# AT32F402 register map
Vendor: Keil; Series: AT32F402; File version: 1.0
CPU: CM4 r0p1, little endian, no MPU, FPU, 4 interrupt priority bits
Registers are 32-bit, read-write, reset 0x0 unless marked. A register's access mark holds for its fields unless they carry their own. Offsets are from the block's base; [hi:lo] are bit positions; 'fields as' and 'values as' point back to an identical list.

## ACC — HICK Auto Clock Calibration
Base 0x40017400
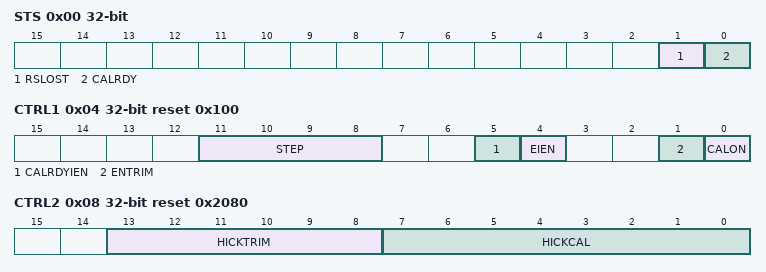
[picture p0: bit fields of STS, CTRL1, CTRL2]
0x00 STS ro — status register
  [1] RSLOST rw — Reference Signal Lost
    0=NotLost (Reference Signal is not lost); 1=Lost (Reference Signal is lost)
  [0] CALRDY rw — Internal high-speed clock calibration ready
    0=NotReady (Interal 8MHz oscillator calibration is not ready); 1=Ready (Interal 8MHz oscillator calibration is ready)
0x04 CTRL1 reset 0x100 — control register 1
  [11:8] STEP — Calibrated step
  [5] CALRDYIEN — CALRDY interrupt enable
    on read: 0=Disabled (Interrupt generation disabled); 1=Enabled (ACC interrupt is generated when CALRDY=1 in the ACC_STS register) | on write: 0=Disable (Interrupt generation disabled); 1=Enable (ACC interrupt is generated when CALRDY=1 in the ACC_STS register)
  [4] EIEN — RSLOST error interrupt enable
    on read: 0=Disabled (Interrupt generation disabled); 1=Enabled (ACC interrupt is generated when RSLOST=1 in the ACC_STS register) | on write: 0=Disable (Interrupt generation disabled); 1=Enable (ACC interrupt is generated when RSLOST=1 in the ACC_STS register)
  [1] ENTRIM — Enable trim
    0=HICKCAL (HICKCAL is calibrated); 1=HICKTRIM (HICKTRIM is calibrated)
  [0] CALON — Calibration on
    on read: 0=Disabled (Calibration disabled); 1=Enabled (Calibration enabled, and starts searching for a pulse on the USB_SOF) | on write: 0=Disable (Calibration disabled); 1=Enable (Calibration enabled, and starts searching for a pulse on the USB_SOF)
0x08 CTRL2 reset 0x2080 — control register 2
  [13:8] HICKTRIM ro — Internal high-speed auto clock trimming
  [7:0] HICKCAL ro — Internal high-speed auto clock calibration
0x0C C1 reset 0x1F2C — compare value 1
  [15:0] C1 — Compare 1
0x10 C2 reset 0x1F40 — compare value 2
  [15:0] C2 — Compare 2
0x14 C3 reset 0x1F54 — compare value 3
  [15:0] C3 — Compare 3

## I2SF5 — Serial peripheral interface
Base 0x40015000
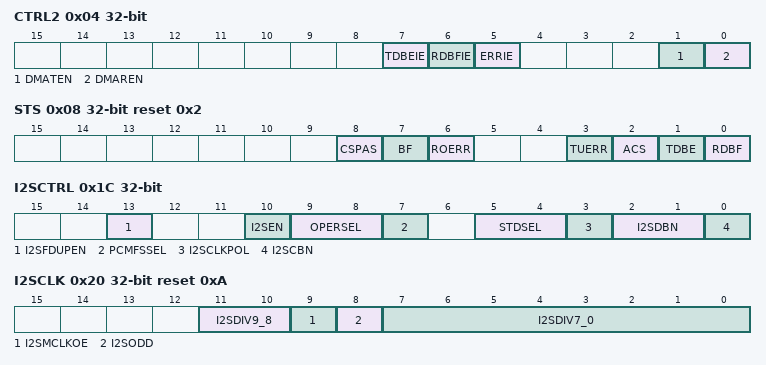
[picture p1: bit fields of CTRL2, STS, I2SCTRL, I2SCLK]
0x04 CTRL2 — control register 2
  [7] TDBEIE — Transmit data buffer empty interrupt enable
  [6] RDBFIE — Receive data buffer full interrupt enable
  [5] ERRIE — Error interrupt enable
  [1] DMATEN — DMA transmit enable
  [0] DMAREN — DMA receive enable
0x08 STS reset 0x2 — status register
  [8] CSPAS — CS pulse abnormal setting fiag
  [7] BF ro — Busy flag
  [6] ROERR ro — Receiver overflow error
  [3] TUERR ro — Transmitter underload error
  [2] ACS ro — Audio channel state
  [1] TDBE ro — Transmit data buffer empty
  [0] RDBF ro — Receive data buffer full
0x0C DT — data register
  [15:0] DT — Data value
0x1C I2SCTRL — I2S control register
  [13] I2SFDUPEN — I2S full duplex mode enable
  [10] I2SEN — I2S Enable
  [9:8] OPERSEL — I2S operation select
  [7] PCMFSSEL — PCM frame synchronization select
  [5:4] STDSEL — I2S standard select
  [3] I2SCLKPOL — I2S clock polarity
  [2:1] I2SDBN — I2S data bit num
  [0] I2SCBN — I2S channel bit num
0x20 I2SCLK reset 0xA — I2S clock register
  [11:10] I2SDIV9_8 — I2S division bit9 and bit8
  [9] I2SMCLKOE — I2S master clock output enable
  [8] I2SODD — Odd result for I2S division
  [7:0] I2SDIV7_0 — I2S division bit7 to bit0
0x30 MISC1
  [0] I2SFPCMCKSEL — I2S PCM clock edge select

## ADCCOM — ADC common area
Base 0x40012300
0x04 CCTRL — Common control register
  [19:16] ADCDIV — ADC division

## DEBUG — Debug support
Base 0xE0042000
0x00 IDCODE ro — DEBUG IDCODE
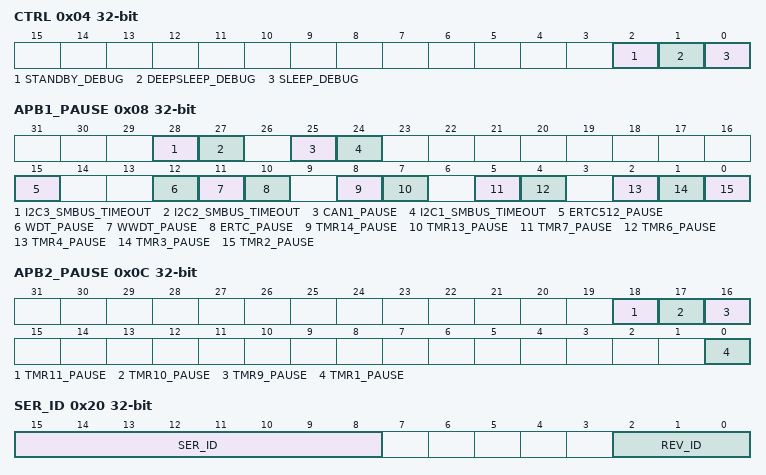
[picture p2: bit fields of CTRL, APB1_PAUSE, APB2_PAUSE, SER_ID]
0x04 CTRL — DEBUG CTRL
  [2] STANDBY_DEBUG — Debug Standby mode control bit
    on read: 0=Disabled (The whole 1.2V digital circuit is unpowered in Standby mode); 1=Enabled (The whole 1.2V digital circuit is not unpowered in Standby mode, and the system clock is provided by the internal RC oscillator (HICK)) | on write: 0=Disable (The whole 1.2V digital circuit is unpowered in Standby mode); 1=Enable (The whole 1.2V digital circuit is not unpowered in Standby mode, and the system clock is provided by the internal RC oscillator (HICK))
  [1] DEEPSLEEP_DEBUG — Debug Deepsleep mode control bit
    on read: 0=Disabled (In Deepsleep mode, all clocks in the 1.2V domain are disabled); 1=Enabled (In Deepsleep mode, system clock is provided by the internal RC oscillator (HICK)) | on write: 0=Disable (In Deepsleep mode, all clocks in the 1.2V domain are disabled); 1=Enable (In Deepsleep mode, system clock is provided by the internal RC oscillator (HICK))
  [0] SLEEP_DEBUG — Debug Sleep mode control bit
    on read: 0=Disabled (When entering Sleep mode, CPU HCLK clock is disabled, but other clocks remain active); 1=Enabled (When entering Sleep mode, all clocks keep running) | on write: 0=Disable (When entering Sleep mode, CPU HCLK clock is disabled, but other clocks remain active); 1=Enable (When entering Sleep mode, all clocks keep running)
0x08 APB1_PAUSE — DEBUG APB1 PAUSE
  [28] I2C3_SMBUS_TIMEOUT
    0=Run (I2C SMBUS timeout control works normally); 1=Stop (I2C SMBUS timeout control stops running)
  [27] I2C2_SMBUS_TIMEOUT
    values as I2C3_SMBUS_TIMEOUT
  [25] CAN1_PAUSE
    0=Run (Running normally); 1=Stopped running
  [24] I2C1_SMBUS_TIMEOUT
    values as I2C3_SMBUS_TIMEOUT
  [15] ERTC512_PAUSE
    0=Run (Running normally); 1=Stopped running
  [12] WDT_PAUSE
    0=Run (Running normally); 1=Stopped running
  [11] WWDT_PAUSE
    0=Run (Running normally); 1=Stopped running
  [10] ERTC_PAUSE
    0=Run (Running normally); 1=Stopped running
  [8] TMR14_PAUSE
    0=Run (Running normally); 1=Stopped running
  [7] TMR13_PAUSE
    0=Run (Running normally); 1=Stopped running
  [5] TMR7_PAUSE
    0=Run (Running normally); 1=Stopped running
  [4] TMR6_PAUSE
    0=Run (Running normally); 1=Stopped running
  [2] TMR4_PAUSE
    0=Run (Running normally); 1=Stopped running
  [1] TMR3_PAUSE
    0=Run (Running normally); 1=Stopped running
  [0] TMR2_PAUSE
    0=Run (Running normally); 1=Stopped running
0x0C APB2_PAUSE — DEBUG APB2 PAUSE
  [all] fields
    0=Run (Running normally); 1=Stopped running
  [18] TMR11_PAUSE
  [17] TMR10_PAUSE
  [16] TMR9_PAUSE
  [0] TMR1_PAUSE
0x20 SER_ID ro — SERIES ID
  [15:8] SER_ID — series ID
  [2:0] REV_ID — version ID
    0=A (Revision A)
